# STM32C5A3 register map
File version: 0.1
CPU: CM33 r0p4, little endian, MPU, FPU, 4 interrupt priority bits
Registers are 32-bit, read-write, reset 0x0 unless marked. A register's access mark holds for its fields unless they carry their own. Offsets are from the block's base; [hi:lo] are bit positions; {n}, {i} and the like mark numbered series.

## CRS — CRS address block description
Base 0x40006000
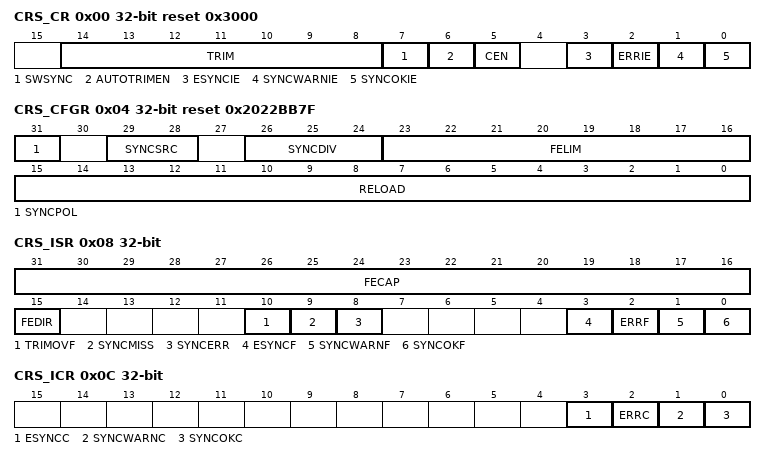
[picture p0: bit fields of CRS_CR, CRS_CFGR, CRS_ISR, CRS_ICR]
0x00 CRS_CR reset 0x3000 — CRS control register
  [14:8] TRIM — HSI144 oscillator smooth trimming
  [7] SWSYNC — Generate software SYNC event
    0=No action; 1=A software SYNC event is generated
  [6] AUTOTRIMEN — Automatic trimming enable
    0=Automatic trimming disabled, TRIM bits can be adjusted by the user; 1=Automatic trimming enabled, TRIM bits are read-only and under hardware control
  [5] CEN — Frequency error counter enable
    0=Frequency error counter disabled; 1=Frequency error counter enabled
  [3] ESYNCIE — Expected SYNC interrupt enable
    0=Expected SYNC (ESYNCF) interrupt disabled; 1=Expected SYNC (ESYNCF) interrupt enabled
  [2] ERRIE — Synchronization or trimming error interrupt enable
    0=Synchronization or trimming error (ERRF) interrupt disabled; 1=Synchronization or trimming error (ERRF) interrupt enabled
  [1] SYNCWARNIE — SYNC warning interrupt enable
    0=SYNC warning (SYNCWARNF) interrupt disabled; 1=SYNC warning (SYNCWARNF) interrupt enabled
  [0] SYNCOKIE — SYNC event OK interrupt enable
    0=SYNC event OK (SYNCOKF) interrupt disabled; 1=SYNC event OK (SYNCOKF) interrupt enabled
0x04 CRS_CFGR reset 0x2022BB7F — CRS configuration register
  [31] SYNCPOL — SYNC polarity selection
    0=SYNC active on rising edge (default); 1=SYNC active on falling edge
  [29:28] SYNCSRC — SYNC signal source selection
    {v}=crs_sync_in_{v} selected as SYNC signal source (v=0..3)
  [26:24] SYNCDIV — SYNC divider
    0=SYNC not divided (default); 1=SYNC divided by 2; 2=SYNC divided by 4; 3=SYNC divided by 8; 4=SYNC divided by 16; 5=SYNC divided by 32; 6=SYNC divided by 64; 7=SYNC divided by 128
  [23:16] FELIM — Frequency error limit
  [15:0] RELOAD — Counter reload value
0x08 CRS_ISR ro — CRS interrupt and status register
  [31:16] FECAP — Frequency error capture
  [15] FEDIR — Frequency error direction
    0=Up-counting direction, the actual frequency is above the target; 1=Down-counting direction, the actual frequency is below the target
  [10] TRIMOVF — Trimming overflow or underflow
    0=No trimming error signaled; 1=Trimming error signaled
  [9] SYNCMISS — SYNC missed
    0=No SYNC missed error signaled; 1=SYNC missed error signaled
  [8] SYNCERR — SYNC error
    0=No SYNC error signaled; 1=SYNC error signaled
  [3] ESYNCF — Expected SYNC flag
    0=No expected SYNC signaled; 1=Expected SYNC signaled
  [2] ERRF — Error flag
    0=No synchronization or trimming error signaled; 1=Synchronization or trimming error signaled
  [1] SYNCWARNF — SYNC warning flag
    0=No SYNC warning signaled; 1=SYNC warning signaled
  [0] SYNCOKF — SYNC event OK flag
    0=No SYNC event OK signaled; 1=SYNC event OK signaled
0x0C CRS_ICR — CRS interrupt flag clear register
  [3] ESYNCC — Expected SYNC clear flag
  [2] ERRC — Error clear flag
  [1] SYNCWARNC — SYNC warning clear flag
  [0] SYNCOKC — SYNC event OK clear flag

## DLYB — DLYB address block description
Base 0x4600F000
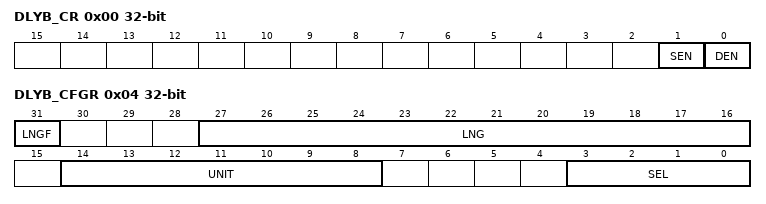
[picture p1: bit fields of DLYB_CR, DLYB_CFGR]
0x00 DLYB_CR — DLYB control register
  [1] SEN — Sampler length enable bit
    0=Sampler length and register access to UNIT[6:0] and SEL[3:0] disabled, output clock enabled; 1=Sampler length and register access to UNIT[6:0] and SEL[3:0] enabled, output clock disabled
  [0] DEN — Delay block enable bit
    0=DLYB disabled; 1=DLYB enabled
0x04 DLYB_CFGR — DLYB configuration register
  [31] LNGF ro — Length valid flag
    0=Length value in LNG is not valid; 1=Length value in LNG is valid
  [27:16] LNG ro — Delay line length value
  [14:8] UNIT — Delay of a unit delay cell.
  [3:0] SEL — Phase for the output clock.

## GPIOA — GPIOA address block description
Base 0x42020000
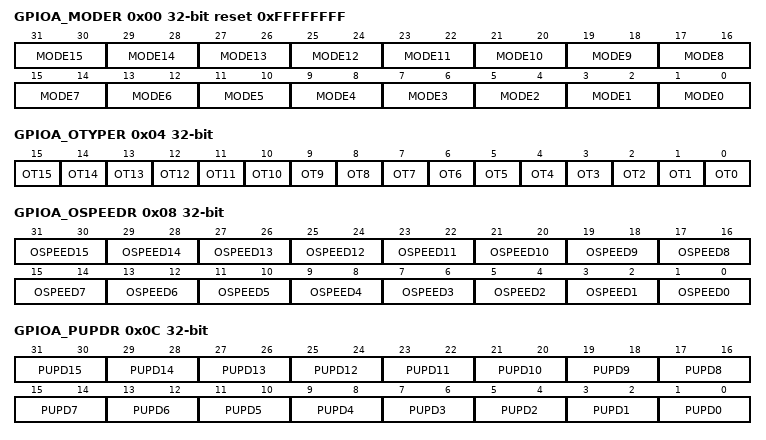
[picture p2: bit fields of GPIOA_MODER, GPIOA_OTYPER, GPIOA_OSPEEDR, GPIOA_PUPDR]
0x00 GPIOA_MODER reset 0xFFFFFFFF — GPIO port mode register
  [all] fields
    0=Input mode; 1=General purpose output mode; 2=Alternate function mode; 3=Analog mode (reset state)
  [2n+1:2n] MODE{n} (n=0..15) — Port x configuration I/O pin y
0x04 GPIOA_OTYPER — GPIO port output type register
  [all] fields
    0=Output push-pull (reset state); 1=Output open-drain
  [n] OT{n} (n=0..15) — Port x configuration I/O pin y
0x08 GPIOA_OSPEEDR — GPIO port output speed register
  [all] fields
    0=Low speed; 1=Medium speed; 2=High speed; 3=Very-high speed
  [2n+1:2n] OSPEED{n} (n=0..15) — Port x configuration I/O pin y
0x0C GPIOA_PUPDR — GPIO port pull-up/pull-down register
  [all] fields
    0=No pull-up, pull-down; 1=Pull-up; 2=Pull-down
  [2n+1:2n] PUPD{n} (n=0..15) — Port x configuration I/O pin y
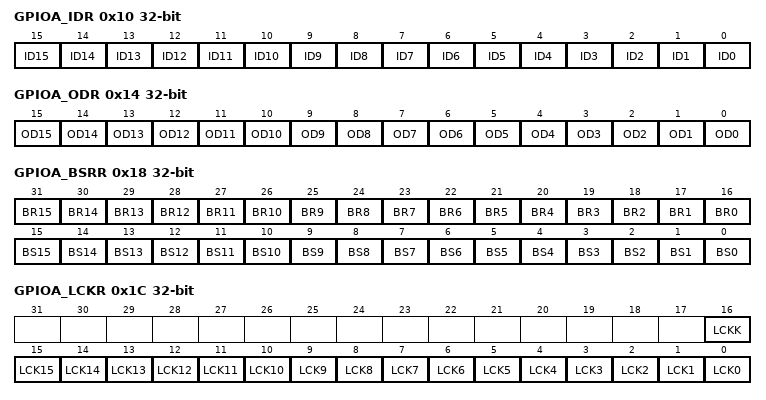
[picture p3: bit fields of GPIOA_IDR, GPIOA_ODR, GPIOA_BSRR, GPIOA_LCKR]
0x10 GPIOA_IDR ro (reset mask 0xFFFF0000) — GPIO port input data register
  [n] ID{n} (n=0..15) — Port x input data I/O pin y
0x14 GPIOA_ODR — GPIO port output data register
  [n] OD{n} (n=0..15) — Port output data I/O pin y
0x18 GPIOA_BSRR wo — GPIO port bit set/reset register
  [n+16] BR{n} (n=0..15) — Port x reset I/O pin y
    0=No action on the corresponding ODy bit; 1=Resets the corresponding ODy bit
  [n] BS{n} (n=0..15) — Port x set I/O pin y
    0=No action on the corresponding ODy bit; 1=Sets the corresponding ODy bit
0x1C GPIOA_LCKR — GPIO port configuration lock register
  [16] LCKK — Lock key
    0=Port configuration lock key not active; 1=Port configuration lock key active
  [n] LCK{n} (n=0..15) — Port x lock I/O pin y
    0=Port configuration not locked; 1=Port configuration locked
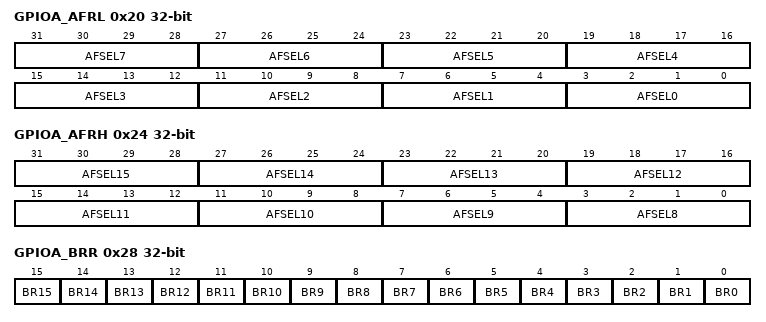
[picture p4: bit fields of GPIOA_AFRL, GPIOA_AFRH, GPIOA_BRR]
0x20 GPIOA_AFRL — GPIO alternate function low register
  [all] fields
    {v}=AF{v} (v=0..15)
  [4n+3:4n] AFSEL{n} (n=0..7) — Alternate function selection for port x I/O pin y
0x24 GPIOA_AFRH — GPIO alternate function high register
  [all] fields
    {v}=AF{v} (v=0..15)
  [4n-29:4n-32] AFSEL{n} (n=8..15) — Alternate function selection for port x I/O pin y
0x28 GPIOA_BRR wo — GPIO port bit reset register
  [all] fields
    0=No action on the corresponding ODy bit; 1=Reset the corresponding ODy bit
  [n] BR{n} (n=0..15) — Port x reset IO pin y

## GPIOB — GPIOB address block description
Base 0x42020400
Registers as GPIOA (with GPIOA read as GPIOB).

## GPIOC — GPIOC address block description
Base 0x42020800
Registers as GPIOA (with GPIOA read as GPIOC).

## GPIOD — GPIOD address block description
Base 0x42020C00
Registers as GPIOA (with GPIOA read as GPIOD).

## GPIOE — GPIOE address block description
Base 0x42021000
Registers as GPIOA (with GPIOA read as GPIOE).

## GPIOF — GPIOF address block description
Base 0x42021400
Registers as GPIOA (with GPIOA read as GPIOF).

## GPIOG — GPIOG address block description
Base 0x42021800
Registers as GPIOA (with GPIOA read as GPIOG).

## GPIOH — GPIOH address block description
Base 0x42021C00
Registers as GPIOA (with GPIOA read as GPIOH).
